AUTOSAR XML (schema 4-3-0)
package /MICROSAR/BswM_swc
  data type mapping set BswMMappingSet  # Contains Mapping for ModeDeclarations Groups which are provided by BswM.
    mode-request-type-maps:
      implementation-data-type=Dcm_DiagnosticSessionControlType, mode-group=DcmDiagnosticSessionControl
      implementation-data-type=Dcm_EcuResetType, mode-group=DcmEcuReset
package /MICROSAR/BswM_swc/ComponentTypes
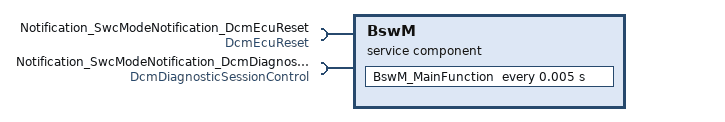
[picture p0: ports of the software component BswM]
  service sw component type BswM: category=SERVICE_COMPONENT
    require port Notification_SwcModeNotification_DcmEcuReset: required-interface=DcmEcuReset
    require port Notification_SwcModeNotification_DcmDiagnosticSessionControl: required-interface=DcmDiagnosticSessionControl
    behavior BswMInternalBehavior: data-type-mapping=BswMMappingSet, handle-termination-and-restart=NO-SUPPORT
      timing event Timer_BswM_MainFunction: start-on-event=BswM_MainFunction, period=0.005
      port-api-options:
        enable-take-address=true, indirect-api=false, port=Notification_SwcModeNotification_DcmEcuReset
        enable-take-address=true, indirect-api=false, port=Notification_SwcModeNotification_DcmDiagnosticSessionControl
      runnable BswM_MainFunction
        mode-access-points:
          Notification_SwcModeNotification_DcmEcuReset.DcmEcuReset
          Notification_SwcModeNotification_DcmDiagnosticSessionControl.DcmDiagnosticSessionControl
  swc implementation BswMImplementation: programming-language=C, behavior=BswMInternalBehavior
